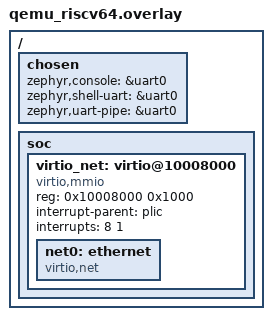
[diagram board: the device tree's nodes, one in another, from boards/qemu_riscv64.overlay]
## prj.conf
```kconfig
# Networking
CONFIG_NETWORKING=y
CONFIG_NET_IPV4=y
CONFIG_NET_L2_ETHERNET=y
CONFIG_NET_ARP=y
CONFIG_NET_SOCKETS=y
CONFIG_NET_TCP=y

# VirtIO driver
CONFIG_VIRTIO=y
CONFIG_VIRTIO_MMIO=y
CONFIG_ETH_VIRTIO_NET=y

# Disable SLIP
CONFIG_SLIP=n

# Console and shell
CONFIG_SERIAL=y
CONFIG_CONSOLE=y
CONFIG_UART_CONSOLE=y
CONFIG_SHELL=y
CONFIG_NET_SHELL=y

# IP configuration
CONFIG_NET_CONFIG_SETTINGS=y
CONFIG_NET_CONFIG_MY_IPV4_ADDR="192.168.100.2"
CONFIG_NET_CONFIG_MY_IPV4_NETMASK="255.255.255.0"
CONFIG_NET_CONFIG_PEER_IPV4_ADDR="192.168.100.1"

# Entropy (required by the network stack)
CONFIG_ENTROPY_GENERATOR=y
CONFIG_TEST_RANDOM_GENERATOR=y

# Memory (needed for virtqueues and the network stack)
CONFIG_HEAP_MEM_POOL_SIZE=16384
CONFIG_SYSTEM_WORKQUEUE_STACK_SIZE=8192

# Default settings for M-Mode
CONFIG_RISCV_MACHINE_TIMER=y
CONFIG_RISCV_SUPERVISOR_TIMER=n
# Supervisor mode (comment the configs below to enable S-Mode)
# CONFIG_RISCV_SBI_BOOT=y
# CONFIG_RISCV_S_MODE=y
# CONFIG_RISCV_SUPERVISOR_TIMER=y
# CONFIG_RISCV_MACHINE_TIMER=n
```

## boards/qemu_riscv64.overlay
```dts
/ {
    chosen {
        zephyr,console = &uart0;
        zephyr,shell-uart = &uart0; 
        zephyr,uart-pipe = &uart0;
    };

    soc {
        virtio_net: virtio@10008000 {
            compatible = "virtio,mmio";
            reg = <0x10008000 0x1000>;
            interrupt-parent = <&plic>;
            interrupts = <8 1>;
            status = "okay";

            net0: ethernet {
                compatible = "virtio,net";
                status = "okay";
            };
        };
    };
};
```

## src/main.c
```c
#include <zephyr/kernel.h>

void main(void)
{
    printk("Zephyr Ready\n");
    printk("Networking initialized\n");
    printk("Do: net iface to see interfaces\n");
    printk("Do: net ping 192.168.100.x to ping localhost\n");
}
```
